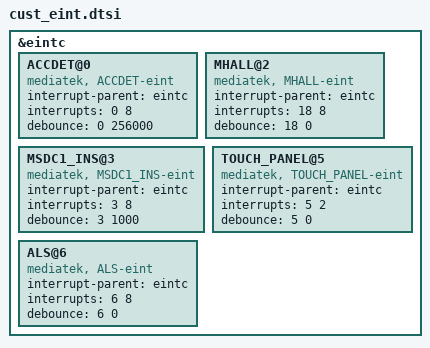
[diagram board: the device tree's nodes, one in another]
/*
 * Generated by MTK SP Drv_CodeGen Version 03.13.6  for MT6580. Copyright MediaTek Inc. (C) 2013.
 * Tue Apr 24 01:11:59 2018
 * Do Not Modify the File.
 */

/*************************
 * EINT DTSI File
*************************/

&eintc {
	ACCDET@0 {
		compatible = "mediatek, ACCDET-eint";
		interrupt-parent = <&eintc>;
		interrupts = <0 8>;
		debounce = <0 256000>;
	};

	MHALL@2 {
		compatible = "mediatek, MHALL-eint";
		interrupt-parent = <&eintc>;
		interrupts = <18 8>;
		debounce = <18 0>;
	};

	MSDC1_INS@3 {
		compatible = "mediatek, MSDC1_INS-eint";
		interrupt-parent = <&eintc>;
		interrupts = <3 8>;
		debounce = <3 1000>;
	};

	TOUCH_PANEL@5 {
		compatible = "mediatek, TOUCH_PANEL-eint";
		interrupt-parent = <&eintc>;
		interrupts = <5 2>;
		debounce = <5 0>;
	};

	ALS@6 {
		compatible = "mediatek, ALS-eint";
		interrupt-parent = <&eintc>;
		interrupts = <6 8>;
		debounce = <6 0>;
	};

};
